# WriteFixture register map
File version: 1
Software-only permissions fixture
Registers are 8-bit, read-write, no defined reset value unless marked. A register's access mark holds for its fields unless they carry their own. Offsets are from the block's base; lines under a group give offsets from that group; [hi:lo] are bit positions; {n}, {i} and the like mark numbered series; 'fields as' and 'values as' point back to an identical list; <NAME> marks a mode.

## Memory map
0x40000000 PORT

## PORT
Base 0x40000000
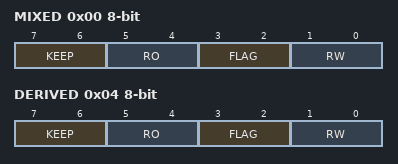
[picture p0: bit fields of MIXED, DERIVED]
0x00 MIXED write-1-clears range 1..3
  [7:6] KEEP write-as-read
  [5:4] RO ro
  [3:2] FLAG
  [1:0] RW
    on read: 2=ReadOnlyName | on write: 0=Off; 1=On
0x04 DERIVED write-1-clears range 1..3
  fields as MIXED
0x08 WO wo
0x0C READ_CLEAR
  [7:0] FLAG read-clears
